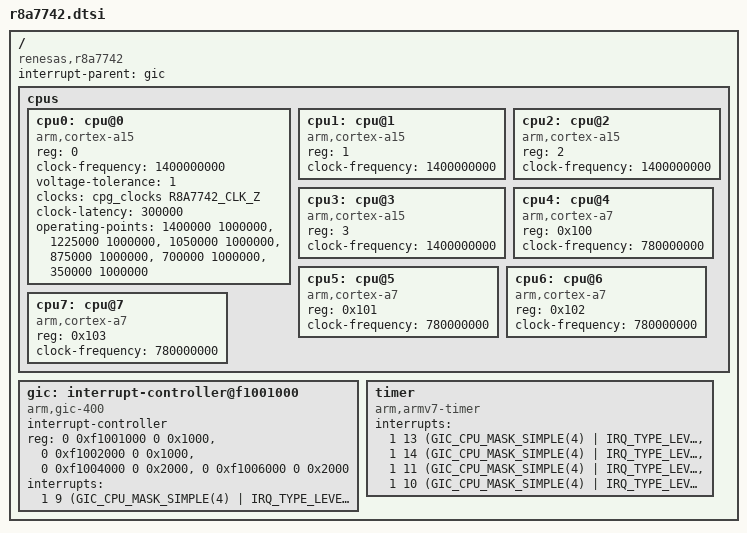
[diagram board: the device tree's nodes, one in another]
/*
 * Device Tree Source for the r8a7742 SoC
 *
 * Copyright (C) 2018 Renesas Electronics Corporation
 * Copyright (C) 2015 Renesas Electronics Corporation
 * Copyright (C) 2013-2014 Renesas Solutions Corp.
 * Copyright (C) 2014 Cogent Embedded Inc.
 *
 * This file is licensed under the terms of the GNU General Public License
 * version 2.  This program is licensed "as is" without any warranty of any
 * kind, whether express or implied.
 */

#include <dt-bindings/clock/r8a7742-clock.h>
#include <dt-bindings/interrupt-controller/arm-gic.h>
#include <dt-bindings/interrupt-controller/irq.h>

/ {
	compatible = "renesas,r8a7742";
	interrupt-parent = <&gic>;
	#address-cells = <2>;
	#size-cells = <2>;

	cpus {
		#address-cells = <1>;
		#size-cells = <0>;

		cpu0: cpu@0 {
			device_type = "cpu";
			compatible = "arm,cortex-a15";
			reg = <0>;
			clock-frequency = <1400000000>;
			voltage-tolerance = <1>; /* 1% */
			clocks = <&cpg_clocks R8A7742_CLK_Z>;
			clock-latency = <300000>; /* 300 us */

			/* kHz - uV - OPPs unknown yet */
			operating-points = <1400000 1000000>,
					<1225000 1000000>,
					<1050000 1000000>,
					< 875000 1000000>,
					< 700000 1000000>,
					< 350000 1000000>;
		};

		cpu1: cpu@1 {
			device_type = "cpu";
			compatible = "arm,cortex-a15";
			reg = <1>;
			clock-frequency = <1400000000>;
		};

		cpu2: cpu@2 {
			device_type = "cpu";
			compatible = "arm,cortex-a15";
			reg = <2>;
			clock-frequency = <1400000000>;
		};

		cpu3: cpu@3 {
			device_type = "cpu";
			compatible = "arm,cortex-a15";
			reg = <3>;
			clock-frequency = <1400000000>;
		};

		cpu4: cpu@4 {
			device_type = "cpu";
			compatible = "arm,cortex-a7";
			reg = <0x100>;
			clock-frequency = <780000000>;
		};

		cpu5: cpu@5 {
			device_type = "cpu";
			compatible = "arm,cortex-a7";
			reg = <0x101>;
			clock-frequency = <780000000>;
		};

		cpu6: cpu@6 {
			device_type = "cpu";
			compatible = "arm,cortex-a7";
			reg = <0x102>;
			clock-frequency = <780000000>;
		};

		cpu7: cpu@7 {
			device_type = "cpu";
			compatible = "arm,cortex-a7";
			reg = <0x103>;
			clock-frequency = <780000000>;
		};
	};

	gic: interrupt-controller@f1001000 {
		compatible = "arm,gic-400";
		#interrupt-cells = <3>;
		#address-cells = <0>;
		interrupt-controller;
		reg = <0 0xf1001000 0 0x1000>,
			<0 0xf1002000 0 0x1000>,
			<0 0xf1004000 0 0x2000>,
			<0 0xf1006000 0 0x2000>;
		interrupts = <1 9 (GIC_CPU_MASK_SIMPLE(4) |
					IRQ_TYPE_LEVEL_HIGH)>;
	};

	timer {
		compatible = "arm,armv7-timer";
		interrupts = <1 13 (GIC_CPU_MASK_SIMPLE(4) |
					IRQ_TYPE_LEVEL_LOW)>,
				<1 14 (GIC_CPU_MASK_SIMPLE(4) |
					IRQ_TYPE_LEVEL_LOW)>,
				<1 11 (GIC_CPU_MASK_SIMPLE(4) |
					IRQ_TYPE_LEVEL_LOW)>,
				<1 10 (GIC_CPU_MASK_SIMPLE(4) |
					IRQ_TYPE_LEVEL_LOW)>;
	};
};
